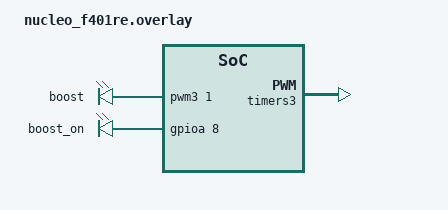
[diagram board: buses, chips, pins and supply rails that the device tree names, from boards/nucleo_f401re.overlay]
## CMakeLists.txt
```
cmake_minimum_required(VERSION 3.20.0)
# Re-direct the directory where the 'boards' directory is found from
# $ZEPHYR_BASE to this directory.
#set(BOARD_ROOT ${CMAKE_CURRENT_LIST_DIR})

set(BOARD nucleo_f401re)
set(SHIELD x_nucleo_idb05a1)

find_package(Zephyr REQUIRED HINTS $ENV{ZEPHYR_BASE})
project(zgeiger)

target_sources(app PRIVATE src/main.c src/boost_drv.c src/cli.c)
```

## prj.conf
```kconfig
CONFIG_FLASH=y
CONFIG_FLASH_MAP=y
CONFIG_FCB=y

CONFIG_SETTINGS_FCB=y
CONFIG_SETTINGS=y
CONFIG_SETTINGS_RUNTIME=y

CONFIG_LOG=y
CONFIG_SHELL=y
CONFIG_SHELL_PROMPT_UART="geiger:~$ "

CONFIG_GPIO=y
CONFIG_PWM=y
```

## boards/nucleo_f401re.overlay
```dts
/ {
    boost_drv_pwms {
        compatible = "pwm-leds";
        status = "okay";
        boost {
            // 5us (200kHz), is a resonant freq for RFS1317-106KL coil
            pwms = <&pwm3 1 PWM_USEC(5) PWM_POLARITY_NORMAL>;
        };
    };
    boost_drv_gpios {
        compatible = "gpio-leds";
        boost_on {
            gpios = <&gpioa 8 GPIO_ACTIVE_HIGH>;
        };
    };
};

&timers3 {
	status = "okay";

	pwm3: pwm {
		status = "okay";
		pinctrl-0 = <&tim3_ch1_pb4>;
		pinctrl-names = "default";
	};
};

&flash0 {
    partitions {
        compatible = "fixed-partitions";
        #address-cells = <1>;
        #size-cells = <1>;

        // first 256K is program
        boot_partition: partition@0 {
            reg = <0x0 DT_SIZE_K(256)>;
            read-only;
        };

        // Set 2 x 128k sector of storage at the end of the flash
        storage_partition: partition@0x40000 {
            label = "storage";
            reg = <0x40000 DT_SIZE_K(256)>;
        };
    };
};
```

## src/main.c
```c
#include <zephyr/kernel.h>
#include <zephyr/logging/log.h>
#include <zephyr/settings/settings.h>

LOG_MODULE_REGISTER(geiger, 4);

#include "boost_drv.h"

int main(void) {
	if (!boost_drv_init()) {
		return -1;
	}
	LOG_INF("Boost driver initialization: OK");
	int rc = settings_subsys_init();
	if (rc) {
		LOG_ERR("settings subsys initialization: fail (err %d)", rc);
		return -2;
	}
	LOG_INF("Settings subsys initialization: OK");
	// ok to exit main, the shell thread keeps running
	return 0;
}
```

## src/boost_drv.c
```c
/**
 * Hi-Voltage boost module
 */

#include <zephyr/drivers/pwm.h>
#include <zephyr/drivers/gpio.h>
#include "log.h"

static const struct pwm_dt_spec boost_pwm = PWM_DT_SPEC_GET(DT_PATH(boost_drv_pwms, boost));
static const struct gpio_dt_spec boost_on = GPIO_DT_SPEC_GET(DT_PATH(boost_drv_gpios, boost_on), gpios);

static bool drv_init;

bool boost_drv_init() {
	if (!gpio_is_ready_dt(&boost_on)) {
		LOG_ERR("Error: boost_on GPIO is not ready");
		return (drv_init = false);;
	}
	if (!device_is_ready(boost_pwm.dev)) {
		LOG_ERR("Error: PWM device %s is not ready", boost_pwm.dev->name);
		return (drv_init = false);
	}
	return (drv_init = true);
}

bool boost_drv_on() {
	unsigned t = boost_pwm.period;
	unsigned p = t * 1 / 2;
	int rc = pwm_set_dt(&boost_pwm, t, p);
	if (rc) {
		LOG_ERR("cannot set pwm, rc=%d", rc);
		return false;
	}
	LOG_DBG("pwm set");
	rc = gpio_pin_configure_dt(&boost_on, GPIO_OUTPUT_ACTIVE);
	if (rc) {
		LOG_ERR("cannot set boost on, rc=%d", rc);
		return false;
	}
	LOG_DBG("boost on set");
	return true;
}

bool boost_drv_off() {
	if (!drv_init) {
		return false;
	}
	int rc = gpio_pin_configure_dt(&boost_on, GPIO_OUTPUT_INACTIVE);
	if (rc) {
		LOG_ERR("cannot unset boost, rc=%d", rc);
		return false;
	}
	LOG_DBG("boost unset");
	rc = pwm_set_dt(&boost_pwm, 0, 0);
	if (rc) {
		LOG_ERR("cannot turn pwm off, rc=%d", rc);
		return false;
	}
	LOG_DBG("pwm unset");
	return true;
}
```

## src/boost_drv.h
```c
#pragma once

#include <stdbool.h>

bool boost_drv_init();

bool boost_drv_on();

bool boost_drv_off();
```

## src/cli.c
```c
#include <zephyr/shell/shell.h>
#include "boost_drv.h"

static int cmd_boost(const struct shell *sh, size_t argc, char **argv, void *data) {
	int on_off = (intptr_t) data;
	bool status = on_off ? boost_drv_on() : boost_drv_off();
	if (status) {
		shell_info(sh, "boost = %s", on_off ? "on" : "off");
	} else {
		shell_error(sh, "could not set boost = %s", on_off ? "on" : "off");
	}
	return status ? 0 : -ENOEXEC;
}

SHELL_SUBCMD_DICT_SET_CREATE(sub_boost_cmds, cmd_boost, (off, 0, "stop"), (on, 1, "start"));

SHELL_STATIC_SUBCMD_SET_CREATE(sub_boost,
                               SHELL_CMD(boost, &sub_boost_cmds, "Start/Stop", NULL),
                               SHELL_SUBCMD_SET_END
);

SHELL_CMD_REGISTER(geiger, &sub_boost, "Boost hi-voltage operation", NULL);
```

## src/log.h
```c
#include <zephyr/logging/log.h>

LOG_MODULE_DECLARE(geiger, LOG_LEVEL_DBG);
```
